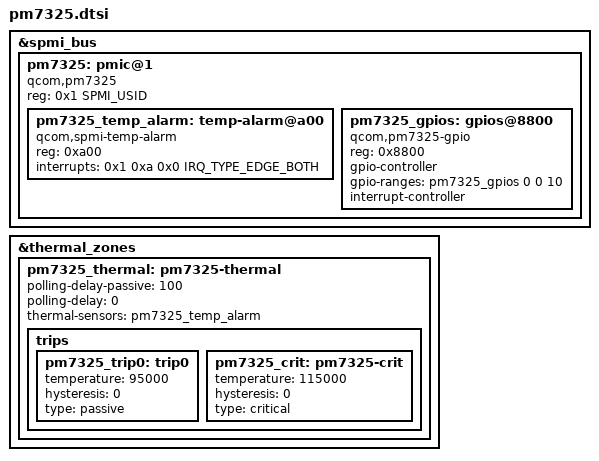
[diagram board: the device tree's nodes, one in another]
// SPDX-License-Identifier: BSD-3-Clause
// Copyright (c) 2021, The Linux Foundation. All rights reserved.

#include <dt-bindings/interrupt-controller/irq.h>
#include <dt-bindings/spmi/spmi.h>

&spmi_bus {
	pm7325: pmic@1 {
		compatible = "qcom,pm7325", "qcom,spmi-pmic";
		reg = <0x1 SPMI_USID>;
		#address-cells = <1>;
		#size-cells = <0>;

		pm7325_temp_alarm: temp-alarm@a00 {
			compatible = "qcom,spmi-temp-alarm";
			reg = <0xa00>;
			interrupts = <0x1 0xa 0x0 IRQ_TYPE_EDGE_BOTH>;
			#thermal-sensor-cells = <0>;
		};

		pm7325_gpios: gpios@8800 {
			compatible = "qcom,pm7325-gpio", "qcom,spmi-gpio";
			reg = <0x8800>;
			gpio-controller;
			gpio-ranges = <&pm7325_gpios 0 0 10>;
			#gpio-cells = <2>;
			interrupt-controller;
			#interrupt-cells = <2>;
		};
	};
};

&thermal_zones {
	pm7325_thermal: pm7325-thermal {
		polling-delay-passive = <100>;
		polling-delay = <0>;
		thermal-sensors = <&pm7325_temp_alarm>;

		trips {
			pm7325_trip0: trip0 {
				temperature = <95000>;
				hysteresis = <0>;
				type = "passive";
			};

			pm7325_crit: pm7325-crit {
				temperature = <115000>;
				hysteresis = <0>;
				type = "critical";
			};
		};
	};
};
